VERSION ""

NS_ :

BS_:

BU_:

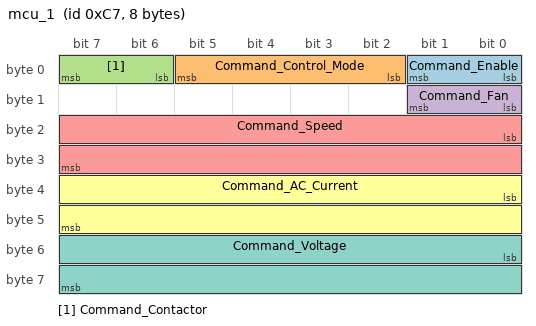
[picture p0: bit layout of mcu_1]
BO_ 199 mcu_1: 8 Vector__XXX
 SG_ Command_Enable : 0|2@1+ (1,0) [0|0] "" Vector__XXX
 SG_ Command_Control_Mode : 2|4@1+ (1,0) [0|0] "" Vector__XXX
 SG_ Command_Contactor : 6|2@1+ (1,0) [0|0] "" Vector__XXX
 SG_ Command_Fan : 8|2@1+ (1,0) [0|0] "" Vector__XXX
 SG_ Command_Speed : 16|16@1+ (1,0) [0|0] "" Vector__XXX
 SG_ Command_AC_Current : 32|16@1+ (1,0) [0|0] "" Vector__XXX
 SG_ Command_Voltage : 48|16@1+ (1,0) [0|0] "" Vector__XXX
